# NM1230_v1 register map
File version: 1.0
NM1230_v1 SVD file
Registers are 32-bit, read-write, reset 0x0 unless marked. A register's access mark holds for its fields unless they carry their own. Offsets are from the block's base; lines under a group give offsets from that group; [hi:lo] are bit positions; {n}, {i} and the like mark numbered series; 'fields as' and 'values as' point back to an identical list; <NAME> marks a mode.

## Memory map
0x40004000 WDT size 0x4 — WDT Register Map
0x40010000 TMR blocks up to offset 0xBC — TMR Register Map
0x40040000 EPWM blocks up to offset 0x88 — EPWM Register Map
0x40070000 UUART0 blocks up to offset 0x68 — UUART Register Map
0x40070000 USPI0 blocks up to offset 0x68 — USPI Register Map
0x40070000 UI2C0 blocks up to offset 0x90 — UI2C Register Map
0x400D0000 ACMP size 0x18 — ACMP Register Map
0x400E0000 ADC blocks up to offset 0x3C — ADC Register Map
0x400F0000 PGA size 0x10 — PGA Register Map
0x40140000 BPWM blocks up to offset 0x80 — BPWM Register Map
0x40170000 UUART1 blocks up to offset 0x68 — UUART Register Map
0x40170000 USPI1 blocks up to offset 0x68 — USPI Register Map
0x40170000 UI2C1 blocks up to offset 0x90 — UI2C Register Map
0x401B0000 ECAP size 0x24 — ECAP Register Map
0x401C0000 QEI blocks up to offset 0x30 — QEI Register Map
0x40270000 UUART2 blocks up to offset 0x68 — UUART Register Map
0x40270000 UI2C2 blocks up to offset 0x90 — UI2C Register Map
0x50000000 SYS blocks up to offset 0x118 — SYS Register Map
0x50000200 CLK blocks up to offset 0x64 — CLK Register Map
0x50000300 INT blocks up to offset 0x88 — INT Register Map
0x50004000 GPIO blocks up to offset 0x954 — GPIO Register Map
0x5000C000 FMC blocks up to offset 0x58 — FMC Register Map
0x50014000 HDIV blocks up to offset 0x8C — HDIV Register Map
0xE000E000 SCS blocks up to offset 0xD24 — SCS Register Map

## INT — INT Register Map
Base 0x50000300
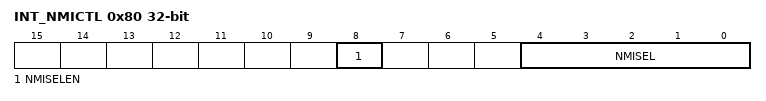
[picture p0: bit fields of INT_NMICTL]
0x80 INT_NMICTL — NMI Source Interrupt Select Control Register
  [8] NMISELEN — NMI Interrupt Enable Control (Write Protected). Note: This bit is the protected bit, and programming it needs to write 0x59, 0x16, and 0x88 to address 0x5000_0100 to disable register protection. Refer to the register SYS_REGLCTL at address SYS_BA+0x100.
    0=NMI interrupt Disabled; 1=NMI interrupt Enabled
  [4:0] NMISEL — NMI Interrupt Source Selection. The NMI interrupt to Cortex-M0 can be selected from one of the peripheral interrupt by setting NMTSEL.
0x84 INT_IRQSTS — MCU IRQ Number Identity Register
  [31:0] IRQ — MCU IRQ Source Register. The IRQ collects all the interrupts from the peripherals and generates the synchronous interrupt to Cortex-M0 core. There is one mode to generate interrupt to Cortex-M0 - the normal mode. The IRQ collects all interrupts from each peripheral and synchronizes them then interrupts the Cortex-M0. When the IRQ[n] is 0, setting IRQ[n] to 1 will generate an interrupt to Cortex-M0 NVIC[n]. When the IRQ[n] is 1 (i.e. an interrupt is assert), setting 1 to the MCU_bit[n] will clear the interrupt and setting IRQ[n] 0 has no effect.

## WDT — WDT Register Map
Base 0x40004000
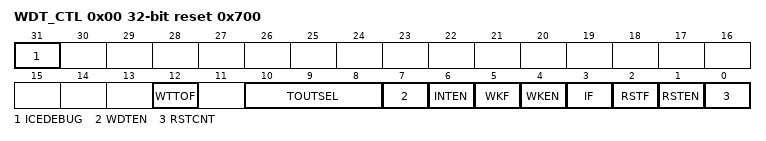
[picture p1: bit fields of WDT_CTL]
0x00 WDT_CTL reset 0x700 — Watchdog Timer Control Register
  [31] ICEDEBUG — ICE Debug Mode Acknowledge Disable Control (Write Protect). WDT up counter will keep going no matter CPU is hanging by ICE or not.
    0=ICE debug mode acknowledgement effects WDT counting; 1=ICE debug mode acknowledgement Disabled
  [12] WTTOF — Watchdog Timer Time-out Flag. This bit will be set to 1 while WDT up counter value reaches the selected WDT time-out interval. Note: This bit is cleared by writing 1 to it.
    0=WDT time-out did not occur; 1=WDT time-out occurred
  [10:8] TOUTSEL — Watchdog Timer Interval Selection(Write Protect). These three bits select the time-out interval for the Watchdog Timer.
    0=24 * TWDT; 1=26 * TWDT; 2=28 * TWDT; 3=210 * TWDT; 4=212 * TWDT; 5=214 * TWDT; 6=216 * TWDT; 7=218 * TWDT
  [7] WDTEN — Watchdog Timer Enable Control (Write Protect)
    0=WDT Disabled. (This action will reset the internal up counter value.); 1=WDT Enabled
  [6] INTEN — Watchdog Timer Time-out Interrupt Enable Control (Write Protect). If this bit is enabled, the WDT time-out interrupt signal is generated and inform to CPU.
    0=WDT time-out interrupt Disabled; 1=WDT time-out interrupt Enabled
  [5] WKF — Watchdog Timer Time-out Wake-up Flag. This bit indicates the interrupt wake-up flag status of WDT. Note: This bit is cleared by writing 1 to it.
    0=WDT does not cause chip wake-up; 1=Chip wake-up from Idle or Power-down mode if WDT time-out interrupt signal generated
  [4] WKEN — Watchdog Timer Time-out Wake-up Function Control (Write Protect). If this bit is set to 1, while IF is generated to 1 and INTEN enabled, the WDT time-out interrupt signal will generate a wake-up trigger event to chip. Note: Chip can be woken-up by WDT time-out interrupt signal generated only if WDT clock source is selected to 10 kHz oscillator.
    0=Wake-up trigger event Disabled if WDT time-out interrupt signal generated; 1=Wake-up trigger event Enabled if WDT time-out interrupt signal generated
  [3] IF — Watchdog Timer Time-out Interrupt Flag. This bit will be set to 1 while WDT up counter value reaches the selected WDT time-out interval and INTEN is enabled. Note: This bit is cleared by writing 1 to it.
    0=WDT time-out interrupt did not occur; 1=WDT time-out interrupt occurred
  [2] RSTF — Watchdog Timer Time-out Reset Flag. This bit indicates the system has been reset by WDT time-out reset or not. Note: This bit is cleared by writing 1 to it.
    0=WDT time-out reset did not occur; 1=WDT time-out reset occurred
  [1] RSTEN — Watchdog Timer Time-out Reset Enable Control (Write Protect). Setting this bit will enable the WDT time-out reset function if the WDT up counter value has not been cleared after the specific WDT reset delay period (1024 * TWDT) expires.
    0=WDT time-out reset function Disabled; 1=WDT time-out reset function Enabled
  [0] RSTCNT — Reset Watchdog Timer Up Counter (Write Protect). Note: This bit will be automatically cleared by hardware.
    0=No effect; 1=Reset the internal 18-bit WDT up counter value
